# nrf54lm20b_application register map
Vendor: Nordic Semiconductor; Series: nrf54l; File version: 1
CPU: CM33 r0p4, little endian, MPU, FPU, 3 interrupt priority bits, 270 interrupts, 4 SAU regions
Registers are 32-bit, read-write, reset 0x0 unless marked. A register's access mark holds for its fields unless they carry their own. Offsets are from the block's base; [hi:lo] are bit positions; {n}, {i} and the like mark numbered series; 'fields as' and 'values as' point back to an identical list.

## GLOBAL_WDT30_S — Watchdog Timer 0
Base 0x50108000
Same registers: GLOBAL_WDT31_NS 0x40109000, GLOBAL_WDT31_S 0x50109000
0x00 TASKS_START wo — Start WDT
  [0] TASKS_START
    1=Trigger task
0x04 TASKS_STOP wo — Stop WDT
  [0] TASKS_STOP
    1=Trigger task
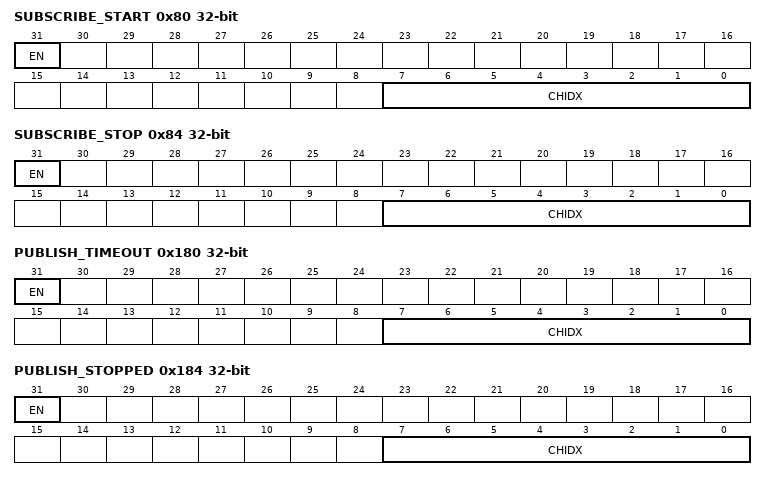
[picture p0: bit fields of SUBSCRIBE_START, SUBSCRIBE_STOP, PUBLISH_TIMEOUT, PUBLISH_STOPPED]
0x80 SUBSCRIBE_START — Subscribe configuration for task START
  [31] EN
    0=Disabled (Disable subscription); 1=Enabled (Enable subscription)
  [7:0] CHIDX — DPPI channel that task START will subscribe to
0x84 SUBSCRIBE_STOP — Subscribe configuration for task STOP
  [31] EN
    values as SUBSCRIBE_START.EN
  [7:0] CHIDX — DPPI channel that task STOP will subscribe to
0x100 EVENTS_TIMEOUT — Watchdog timeout
  [0] EVENTS_TIMEOUT
    0=NotGenerated (Event not generated); 1=Generated (Event generated)
0x104 EVENTS_STOPPED — Watchdog stopped
  [0] EVENTS_STOPPED
    values as EVENTS_TIMEOUT.EVENTS_TIMEOUT
0x180 PUBLISH_TIMEOUT — Publish configuration for event TIMEOUT
  [31] EN
    0=Disabled (Disable publishing); 1=Enabled (Enable publishing)
  [7:0] CHIDX — DPPI channel that event TIMEOUT will publish to
0x184 PUBLISH_STOPPED — Publish configuration for event STOPPED
  [31] EN
    values as PUBLISH_TIMEOUT.EN
  [7:0] CHIDX — DPPI channel that event STOPPED will publish to
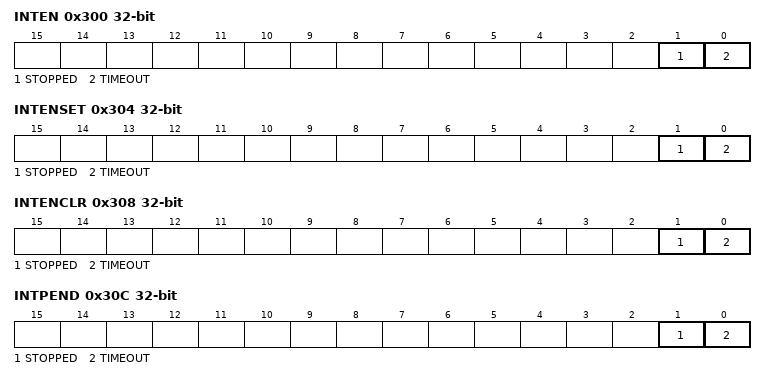
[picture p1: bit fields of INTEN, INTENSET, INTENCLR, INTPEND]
0x300 INTEN — Enable or disable interrupt
  [1] STOPPED — Enable or disable interrupt for event STOPPED
    0=Disabled; 1=Enabled
  [0] TIMEOUT — Enable or disable interrupt for event TIMEOUT
    0=Disabled; 1=Enabled
0x304 INTENSET — Enable interrupt
  [1] STOPPED write-1-sets — Write '1' to enable interrupt for event STOPPED
    on read: 0=Disabled (Read: Disabled); 1=Enabled (Read: Enabled) | on write: 1=Set (Enable)
  [0] TIMEOUT write-1-sets — Write '1' to enable interrupt for event TIMEOUT
    values as STOPPED
0x308 INTENCLR — Disable interrupt
  [1] STOPPED write-1-clears — Write '1' to disable interrupt for event STOPPED
    on read: 0=Disabled (Read: Disabled); 1=Enabled (Read: Enabled) | on write: 1=Clear (Disable)
  [0] TIMEOUT write-1-clears — Write '1' to disable interrupt for event TIMEOUT
    values as STOPPED
0x30C INTPEND ro — Pending interrupts
  [1] STOPPED — Read pending status of interrupt for event STOPPED
    on read: 0=NotPending (Read: Not pending); 1=Pending (Read: Pending)
  [0] TIMEOUT — Read pending status of interrupt for event TIMEOUT
    values as STOPPED
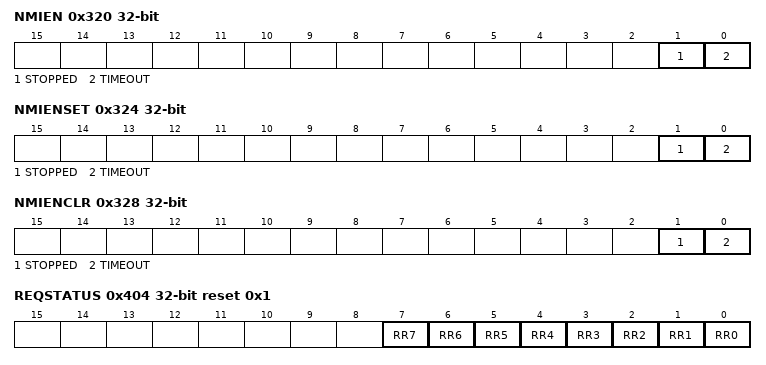
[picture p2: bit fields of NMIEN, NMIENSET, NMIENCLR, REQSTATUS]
0x320 NMIEN — Enable or disable interrupt
  fields as INTEN
0x324 NMIENSET — Enable interrupt
  fields as INTENSET
0x328 NMIENCLR — Disable interrupt
  fields as INTENCLR
0x400 RUNSTATUS ro
  [0] RUNSTATUSWDT — Indicates whether or not WDT is running
    0=NotRunning (Watchdog is not running); 1=Running (Watchdog is running)
0x404 REQSTATUS ro reset 0x1 — Request status
  [n] RR{n} (n=0..7) — Request status for RR[{n}] register
    0=DisabledOrRequested (RR[{n}] register is not enabled, or are already requesting reload); 1=EnabledAndUnrequested (RR[{n}] register is enabled, and are not yet requesting reload)
0x504 CRV reset 0xFFFFFFFF — Counter reload value
  [31:0] CRV — Counter reload value in number of cycles of the 32.768 kHz clock
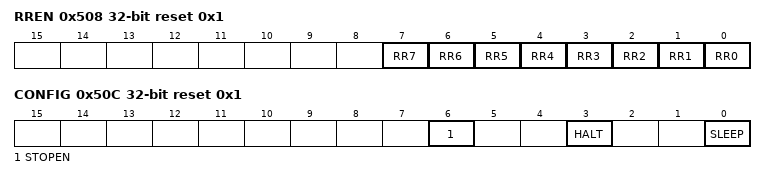
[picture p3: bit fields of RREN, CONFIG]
0x508 RREN reset 0x1 — Enable register for reload request registers
  [n] RR{n} (n=0..7) — Enable or disable RR[{n}] register
    0=Disabled (Disable RR[{n}] register); 1=Enabled (Enable RR[{n}] register)
0x50C CONFIG reset 0x1 — Configuration register
  [6] STOPEN — Allow stopping WDT
    0=Disable (Do not allow stopping WDT); 1=Enable (Allow stopping WDT)
  [3] HALT — Configure WDT to either be paused, or kept running, while the CPU is halted by the debugger
    0=Pause WDT while the CPU is halted by the debugger; 1=Run (Keep WDT running while the CPU is halted by the debugger)
  [0] SLEEP — Configure WDT to either be paused, or kept running, while the CPU is sleeping
    0=Pause WDT while the CPU is sleeping; 1=Run (Keep WDT running while the CPU is sleeping)
0x520 TSEN wo — Task stop enable
  [31:0] TSEN — Allow stopping WDT
    0x6E524635=Enable (Value to allow stopping WDT)
{0x600+4i} RR[{i}] (i=0..7) wo — Description collection: Reload request n
  [31:0] RR — Reload request register
    0x6E524635=Reload (Value to request a reload of the watchdog timer)
